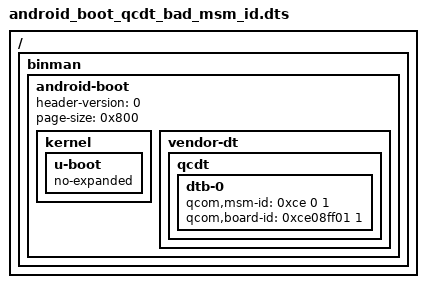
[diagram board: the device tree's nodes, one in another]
// SPDX-License-Identifier: GPL-2.0+

/dts-v1/;

/ {
	#address-cells = <1>;
	#size-cells = <1>;

	binman {
		android-boot {
			header-version = <0>;
			page-size = <0x800>;

			kernel {
				u-boot {
					no-expanded;
				};
			};

			vendor-dt {
				qcdt {
					dtb-0 {
						qcom,msm-id = <0xce 0 1>;
						qcom,board-id = <0xce08ff01 1>;
					};
				};
			};
		};
	};
};
